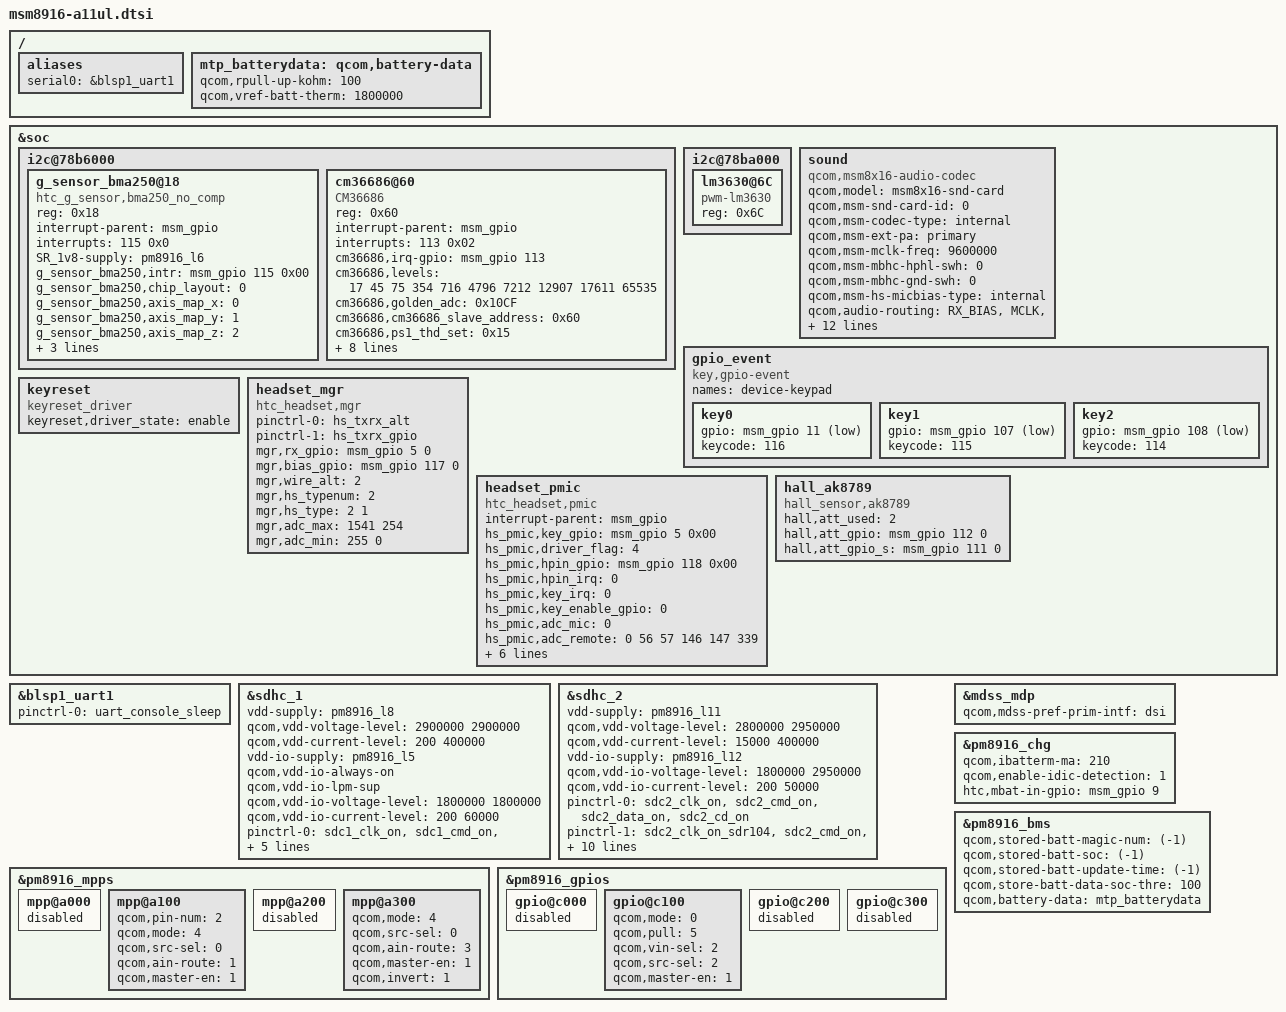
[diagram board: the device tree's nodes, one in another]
/* Copyright (c) 2014, The Linux Foundation. All rights reserved.
 *
 * This program is free software; you can redistribute it and/or modify
 * it under the terms of the GNU General Public License version 2 and
 * only version 2 as published by the Free Software Foundation.
 *
 * This program is distributed in the hope that it will be useful,
 * but WITHOUT ANY WARRANTY; without even the implied warranty of
 * MERCHANTABILITY or FITNESS FOR A PARTICULAR PURPOSE.  See the
 * GNU General Public License for more details.
 */

#include "msm8916.dtsi"
#include "msm8916-pinctrl.dtsi"
#include "msm8916-camera-sensor-a11.dtsi"
#include "dsi-panel-a11.dtsi"
#include "msm8916-touch-a11ul-config.dtsi"

/ {
	aliases {
		serial0 = &blsp1_uart1;
	};
};

&soc {
	i2c@78b6000 {
		g_sensor_bma250@18 {
			compatible = "htc_g_sensor,bma250_no_comp";
			reg = <0x18>;
			interrupt-parent = <&msm_gpio>;
			interrupts = <115 0x0>;
			SR_1v8-supply = <&pm8916_l6>;
			g_sensor_bma250,intr        = <&msm_gpio 115 0x00>;
			g_sensor_bma250,chip_layout = <0>;
			g_sensor_bma250,axis_map_x  = <0>;
			g_sensor_bma250,axis_map_y  = <1>;
			g_sensor_bma250,axis_map_z  = <2>;
			g_sensor_bma250,negate_x    = <0>;
			g_sensor_bma250,negate_y    = <1>;
			g_sensor_bma250,negate_z    = <1>;
		};
		cm36686@60 {
			compatible = "CM36686";
			reg = <0x60>;
			interrupt-parent = <&msm_gpio>;
			interrupts = <113 0x02>;
			interrupt-names = "cm36686";
			cm36686,irq-gpio = <&msm_gpio 113 0x00>;
			cm36686,levels = <17 45 75 354 716 4796 7212 12907 17611 65535>;
			cm36686,golden_adc = <0x10CF>;
			cm36686,cm36686_slave_address = <0x60>;
			cm36686,ps1_thd_set = <0x15>;
			cm36686,ps1_thd_no_cal = <0x5f>;
			cm36686,dynamical_threshold = <1>;
			cm36686,dark_level = <3>;
			cm36686,ps_duty = <0>;
			cm36686,ps_pers = <1>;
			cm36686,ps_it = <7>;
			cm36686,ps_hd = <0>;
			cm36686,ps_led_current = <2>;

		};

	};

	i2c@78ba000 { /* BLSP1 QUP6 */
		lm3630@6C {
			compatible = "pwm-lm3630";
			reg = <0x6C>;
		};
	};

	sound {
		compatible = "qcom,msm8x16-audio-codec";
		qcom,model = "msm8x16-snd-card";
		qcom,msm-snd-card-id = <0>;
		qcom,msm-codec-type = "internal";
		qcom,msm-ext-pa = "primary";
		qcom,msm-mclk-freq = <9600000>;
		qcom,msm-mbhc-hphl-swh = <0>;
		qcom,msm-mbhc-gnd-swh = <0>;
		qcom,msm-hs-micbias-type = "internal";
		qcom,audio-routing =
			"RX_BIAS", "MCLK",
			"SPK_RX_BIAS", "MCLK",
			"INT_LDO_H", "MCLK",
			"AMIC2", "MCLK",
			"MIC BIAS External", "Handset Mic",
			"MIC BIAS Internal2", "Headset Mic",
			"MIC BIAS External", "Secondary Mic",
			"AMIC1", "MIC BIAS External",
			"AMIC3", "MIC BIAS External";
		pinctrl-names = "cdc_lines_act",
				"cdc_lines_sus",
				"cross_conn_det_act",
				"cross_conn_det_sus";
		pinctrl-0 = <&cdc_pdm_lines_act>;
		pinctrl-1 = <&cdc_pdm_lines_sus>;
		pinctrl-2 = <&cross_conn_det_act>;
		pinctrl-3 = <&cross_conn_det_sus>;
		qcom,cdc-us-euro-gpios = <&msm_gpio 120 0>;
		htc,aud-digital-mic-en = <0>;
		htc,aud-24b-en = <1>;
	};
};

&blsp1_uart1 {
	status = "ok";
	pinctrl-names = "default";
	pinctrl-0 = <&uart_console_sleep>;
};

&soc {
	gpio_event {
	compatible = "key,gpio-event";
	names = "device-keypad";
	//clr_gpio = <&msm_gpio 34 0>;
	//cmcc_disable_reset = <1>;

		key0 {
			gpio    = <&msm_gpio 11 3>;
			keycode = <116>;	//pwr
			//pull = <1>;		//0=pull up, 1=no pull
		};
		key1 {
			gpio    = <&msm_gpio 107 3>;
			keycode = <115>;	//vUP
		};
		key2 {
			gpio    = <&msm_gpio 108 3>;
			keycode = <114>;	//vDN
		};
	};

	keyreset {
		compatible = "keyreset_driver";
		keyreset,driver_state = "enable";
	};

	headset_mgr {
		compatible   = "htc_headset,mgr";
		pinctrl-names = "hs_txrx_pin_alt","hs_txrx_pin_gpio";
		pinctrl-0 = <&hs_txrx_alt>;
		pinctrl-1 = <&hs_txrx_gpio>;
		//mgr,tx_gpio  = <&msm_gpio 4 0>;//Pin 4 =NA
		mgr,rx_gpio  = <&msm_gpio 5 0>;
		//mgr,oe_gpio  = <&msm_gpio 4 0>;//Pin 4 =NA
		mgr,bias_gpio  = <&msm_gpio 117 0>;
		mgr,wire_alt = <2>;
		mgr,hs_typenum   = <2>;
		mgr,hs_type      = <2 1>;
		mgr,adc_max      = <1541 254>;
		mgr,adc_min      = <255 0>;
	};

	headset_pmic {
		compatible = "htc_headset,pmic";
		interrupt-parent = <&msm_gpio>;
		hs_pmic,key_gpio 	= <&msm_gpio 5 0x00>;
		hs_pmic,driver_flag     = <4>;
		hs_pmic,hpin_gpio       = <&msm_gpio 118 0x00>;
		hs_pmic,hpin_irq        = <0>;
		hs_pmic,key_irq         = <0>;
		hs_pmic,key_enable_gpio = <0>;
		hs_pmic,adc_mic         = <0>;
		hs_pmic,adc_remote      = <0 56 57 146 147 339>;
		hs_pmic,adc_channel	= <19>;		//mpp4
		hs_pmic,adc_mpp         = <0>;
		hs_pmic,adc_amux        = <0>;
		hs_pmic,hs_controller   = <0>;
		hs_pmic,hs_switch       = <0>;
		qcom,headset-vadc	= <&pm8916_vadc>;
	};

//	headset_onewire {
//		compatible = "htc_headset,1wire";
//		hs_1wire,tx_level_shift_en = <&msm_gpio 3 0x00>;
//		hs_1wire,one_wire_remote = <0x7E 0x7F 0x7D 0x7F 0x7B 0x7F>;
//		hs_1wire,onewire_tty_dev = "ttyHSL1";
//	};

	hall_ak8789 {
		compatible = "hall_sensor,ak8789";
		hall,att_used = <2>;
		hall,att_gpio = <&msm_gpio 112 0>;
		hall,att_gpio_s = <&msm_gpio 111 0>;
	};
};

&sdhc_1 {
	vdd-supply = <&pm8916_l8>;
	qcom,vdd-voltage-level = <2900000 2900000>;
	qcom,vdd-current-level = <200 400000>;

	vdd-io-supply = <&pm8916_l5>;
	qcom,vdd-io-always-on;
	qcom,vdd-io-lpm-sup;
	qcom,vdd-io-voltage-level = <1800000 1800000>;
	qcom,vdd-io-current-level = <200 60000>;

	pinctrl-names = "active", "sleep";
	pinctrl-0 = <&sdc1_clk_on &sdc1_cmd_on &sdc1_data_on>;
	pinctrl-1 = <&sdc1_clk_off &sdc1_cmd_off &sdc1_data_off>;
	htc,slot-type = <0>;
	qcom,nonremovable;

	status = "ok";
};

&sdhc_2 {
	vdd-supply = <&pm8916_l11>;
	qcom,vdd-voltage-level = <2800000 2950000>;
	qcom,vdd-current-level = <15000 400000>;

	vdd-io-supply = <&pm8916_l12>;
	qcom,vdd-io-voltage-level = <1800000 2950000>;
	qcom,vdd-io-current-level = <200 50000>;

	pinctrl-names = "active", "active_sdr104", "sleep";
	pinctrl-0 = <&sdc2_clk_on &sdc2_cmd_on &sdc2_data_on &sdc2_cd_on>;
	pinctrl-1 = <&sdc2_clk_on_sdr104 &sdc2_cmd_on &sdc2_data_on &sdc2_cd_on>;
	pinctrl-2 = <&sdc2_clk_off &sdc2_cmd_off &sdc2_data_off &sdc2_cd_off>;

	#address-cells = <0>;
	interrupt-parent = <&sdhc_2>;
	interrupts = <0 1 2>;
	#interrupt-cells = <1>;
	interrupt-map-mask = <0xffffffff>;
	interrupt-map = <0 &intc 0 125 0
			1 &intc 0 221 0
			2 &msm_gpio 38 0>;
	interrupt-names = "hc_irq", "pwr_irq", "status_irq";
	cd-gpios = <&msm_gpio 38 0x1>;
	htc,slot-type = <1>;

	status = "ok";
};

&pm8916_mpps {
	mpp@a000 { /* MPP 1 */
		/* VDD_PX */
		status = "disabled";
	};

	mpp@a100 { /* MPP 2 */
		/* HR LED */
		qcom,pin-num = <2>;
                qcom,mode      = <4>;   //QPNP_PIN_MODE_AIN
                qcom,src-sel   = <0>;   //QPNP_PIN_SEL_FUNC_CONSTANT
                qcom,ain-route = <1>;   //QPNP_PIN_AIN_AMUX_CH8
                qcom,master-en = <1>;   //ENABLE FEATURE
	};

	mpp@a200 { /* MPP 3 */
		/* VREF DAC */
		status = "disabled";
	};

	mpp@a300 { /* MPP 4 */
		/* Headset Remote Sensor used*/
		qcom,mode      = <4>;  //QPNP_PIN_MODE_AIN
		qcom,src-sel   = <0>;  //QPNP_PIN_SEL_FUNC_CONSTANT
		qcom,ain-route = <3>;  //QPNP_PIN_AIN_AMUX_CH
		qcom,master-en = <1>;  //ENABLE FEATURE
		qcom,invert = <1>;
	};
};

&pm8916_gpios {
	gpio@c000 { /* GPIO 1 */
		/* Battery UICC Alarm */
		status = "disabled";
	};

	gpio@c100 { /* GPIO 2 */
		/* NFC_CLK_REQ */
		qcom,mode = <0>; /* QPNP_PIN_MODE_DIG_IN */
		qcom,pull = <5>; /* QPNP_PIN_PULL_NO */
		qcom,vin-sel = <2>; /* QPNP_PIN_VIN2 */
		qcom,src-sel = <2>; /* QPNP_PIN_SEL_FUNC_1 */
		qcom,master-en = <1>;
	};

	gpio@c200 { /* GPIO 3 */
		/* External regulator control for WTR */
		status = "disabled";
	};

	gpio@c300 { /* GPIO 4 */
		/* External regulator control for APC */
		status = "disabled";
	};
};

&mdss_mdp {
	qcom,mdss-pref-prim-intf = "dsi";
};

&pm8916_chg {
	qcom,ibatterm-ma = <210>;
    qcom,enable-idic-detection = <1>;
	htc,mbat-in-gpio = <&msm_gpio 9 0>;
	status = "ok";
};

/ {
	mtp_batterydata: qcom,battery-data {
		qcom,rpull-up-kohm = <100>;
		qcom,vref-batt-therm = <1800000>;

		#include "batterydata-a11-8x16-id1.dtsi"
		#include "batterydata-a11-8x16-id2.dtsi"
		#include "batterydata-a11-8x16-unknown.dtsi"
	};
};

&pm8916_bms {
	qcom,stored-batt-magic-num= <(-1)>;
	qcom,stored-batt-soc= <(-1)>;
	qcom,stored-batt-update-time= <(-1)>;
	qcom,store-batt-data-soc-thre = <100>;
	status = "ok";
	qcom,battery-data = <&mtp_batterydata>;
};
